# STM32L4P5AEI6 register map
File version: 1.0
Registers are 32-bit, access not given, reset 0x0 unless marked. A register's access mark holds for its fields unless they carry their own. Offsets are from the block's base; [hi:lo] are bit positions; {n}, {i} and the like mark numbered series.

## ADC1
Base 0x50040000
Same registers: ADC2 0x50040100
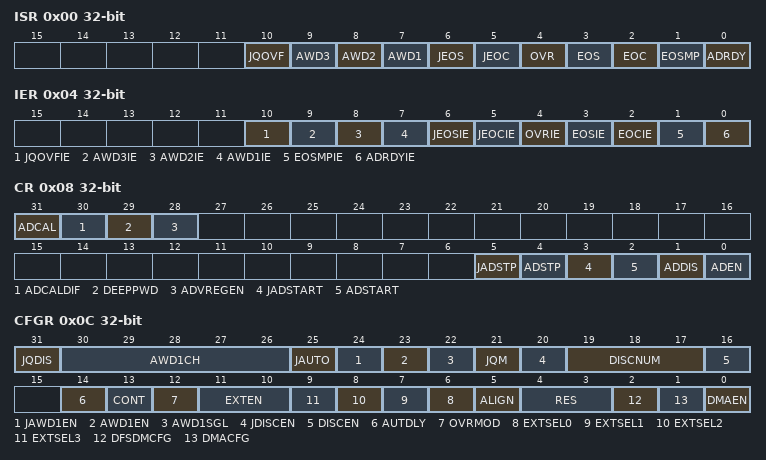
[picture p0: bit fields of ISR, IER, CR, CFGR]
0x00 ISR
  [10] JQOVF, [9] AWD3, [8] AWD2, [7] AWD1, [6] JEOS, [5] JEOC, [4] OVR, [3] EOS, [2] EOC, [1] EOSMP, [0] ADRDY
0x04 IER
  [10] JQOVFIE, [9] AWD3IE, [8] AWD2IE, [7] AWD1IE, [6] JEOSIE, [5] JEOCIE, [4] OVRIE, [3] EOSIE, [2] EOCIE, [1] EOSMPIE, [0] ADRDYIE
0x08 CR
  [31] ADCAL, [30] ADCALDIF, [29] DEEPPWD, [28] ADVREGEN, [5] JADSTP, [4] ADSTP, [3] JADSTART, [2] ADSTART, [1] ADDIS, [0] ADEN
0x0C CFGR
  [31] JQDIS, [30:26] AWD1CH, [25] JAUTO, [24] JAWD1EN, [23] AWD1EN, [22] AWD1SGL, [21] JQM, [20] JDISCEN, [19:17] DISCNUM, [16] DISCEN, [14] AUTDLY, [13] CONT, [12] OVRMOD, [11:10] EXTEN, [n+6] EXTSEL{n} (n=0..3), [5] ALIGN, [4:3] RES, [2] DFSDMCFG, [1] DMACFG, [0] DMAEN
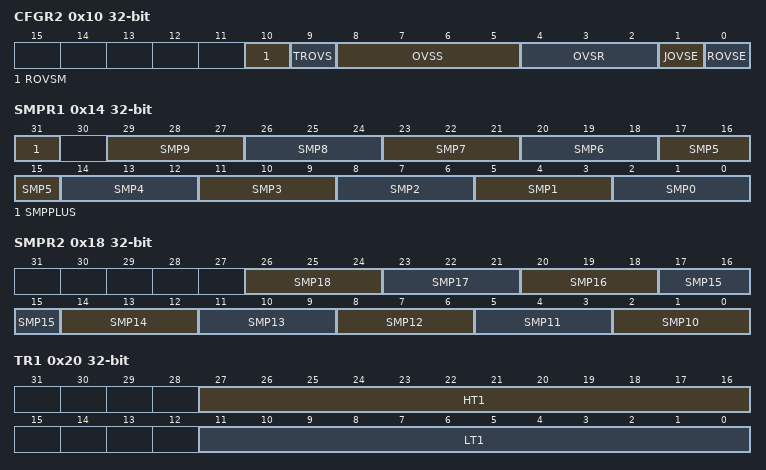
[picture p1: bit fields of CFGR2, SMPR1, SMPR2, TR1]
0x10 CFGR2
  [10] ROVSM, [9] TROVS, [8:5] OVSS, [4:2] OVSR, [1] JOVSE, [0] ROVSE
0x14 SMPR1
  [31] SMPPLUS, [3n+2:3n] SMP{n} (n=0..9)
0x18 SMPR2
  [3n-28:3n-30] SMP{n} (n=10..18)
0x20 TR1
  [27:16] HT1, [11:0] LT1
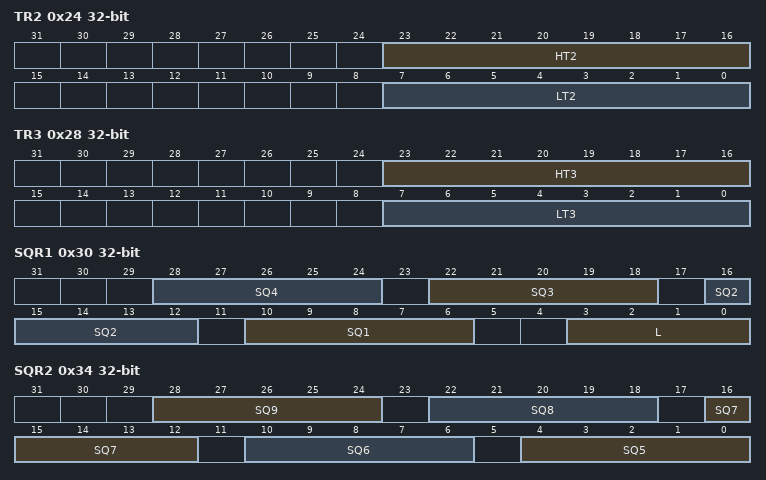
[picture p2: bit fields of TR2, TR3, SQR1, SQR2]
0x24 TR2
  [23:16] HT2, [7:0] LT2
0x28 TR3
  [23:16] HT3, [7:0] LT3
0x30 SQR1
  [6n+4:6n] SQ{n} (n=1..4), [3:0] L
0x34 SQR2
  [6n-26:6n-30] SQ{n} (n=5..9)
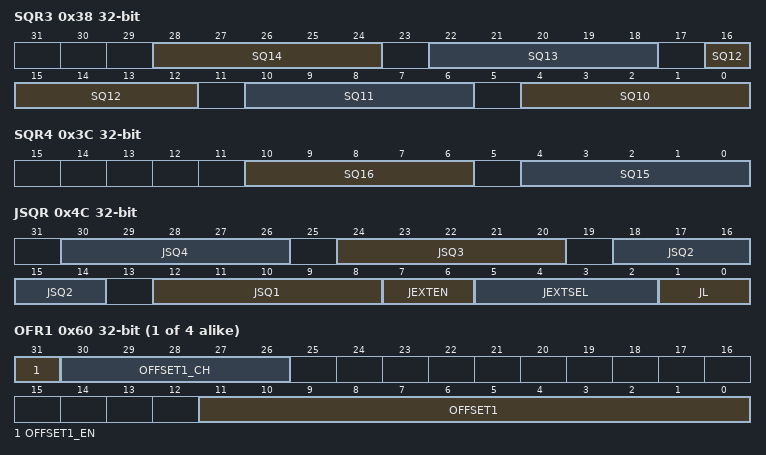
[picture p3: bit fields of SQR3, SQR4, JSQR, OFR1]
0x38 SQR3
  [6n-56:6n-60] SQ{n} (n=10..14)
0x3C SQR4
  [10:6] SQ16, [4:0] SQ15
0x40 DR
  [15:0] RDATA
0x4C JSQR
  [6n+6:6n+2] JSQ{n} (n=1..4), [7:6] JEXTEN, [5:2] JEXTSEL, [1:0] JL
{0x5C+4i} OFR{i} (i=1..4)
  [31] OFFSET{i}_EN, [30:26] OFFSET{i}_CH, [11:0] OFFSET{i}
{0x7C+4i} JDR{i} (i=1..4)
  [15:0] JDATA{i}
0xA0 AWD2CR
  [18:0] AWD2CH
0xA4 AWD3CR
  [18:0] AWD3CH
0xB0 DIFSEL
  [18:0] DIFSEL
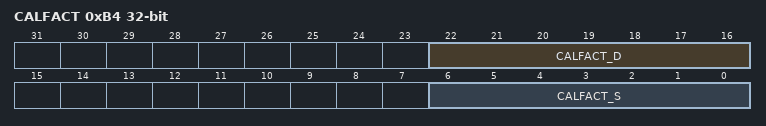
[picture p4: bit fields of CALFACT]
0xB4 CALFACT
  [22:16] CALFACT_D, [6:0] CALFACT_S

## DCMI
Base 0x50050000
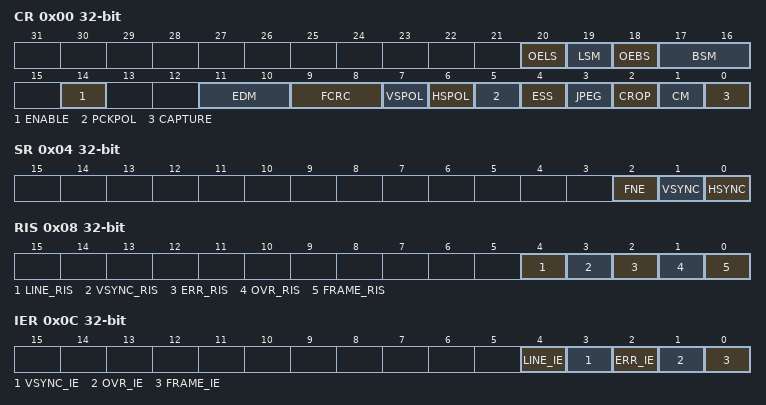
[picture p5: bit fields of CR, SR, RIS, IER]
0x00 CR
  [20] OELS, [19] LSM, [18] OEBS, [17:16] BSM, [14] ENABLE, [11:10] EDM, [9:8] FCRC, [7] VSPOL, [6] HSPOL, [5] PCKPOL, [4] ESS, [3] JPEG, [2] CROP, [1] CM, [0] CAPTURE
0x04 SR
  [2] FNE, [1] VSYNC, [0] HSYNC
0x08 RIS
  [4] LINE_RIS, [3] VSYNC_RIS, [2] ERR_RIS, [1] OVR_RIS, [0] FRAME_RIS
0x0C IER
  [4] LINE_IE, [3] VSYNC_IE, [2] ERR_IE, [1] OVR_IE, [0] FRAME_IE
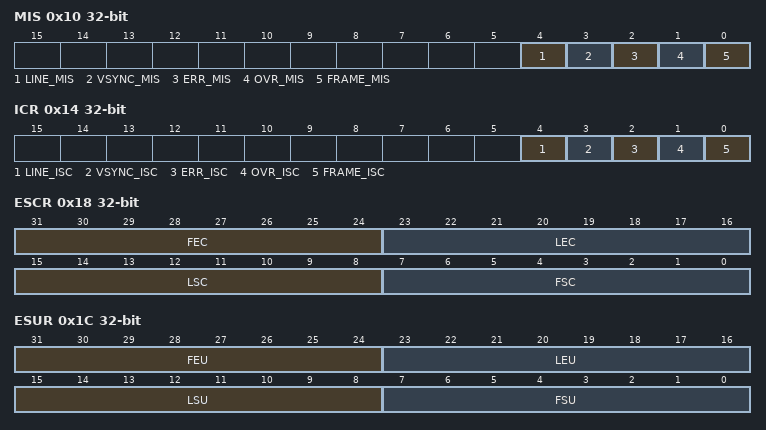
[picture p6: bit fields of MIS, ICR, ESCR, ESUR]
0x10 MIS
  [4] LINE_MIS, [3] VSYNC_MIS, [2] ERR_MIS, [1] OVR_MIS, [0] FRAME_MIS
0x14 ICR
  [4] LINE_ISC, [3] VSYNC_ISC, [2] ERR_ISC, [1] OVR_ISC, [0] FRAME_ISC
0x18 ESCR
  [31:24] FEC, [23:16] LEC, [15:8] LSC, [7:0] FSC
0x1C ESUR
  [31:24] FEU, [23:16] LEU, [15:8] LSU, [7:0] FSU
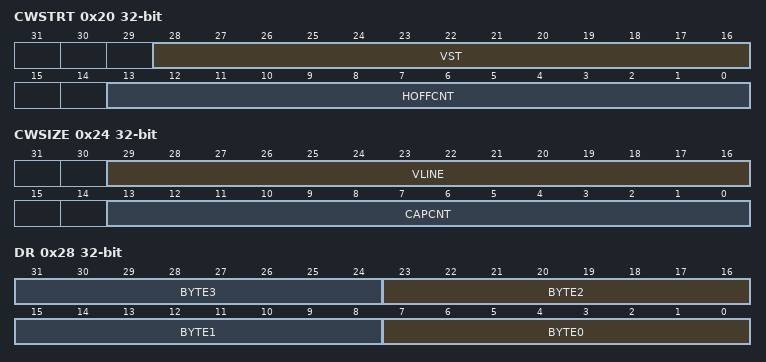
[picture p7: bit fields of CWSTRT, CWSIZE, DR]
0x20 CWSTRT
  [28:16] VST, [13:0] HOFFCNT
0x24 CWSIZE
  [29:16] VLINE, [13:0] CAPCNT
0x28 DR
  [8n+7:8n] BYTE{n} (n=0..3)

## PSSI
Base 0x50050400
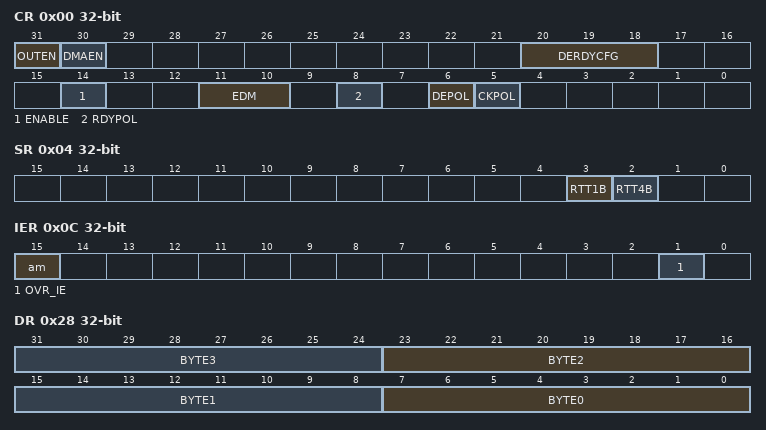
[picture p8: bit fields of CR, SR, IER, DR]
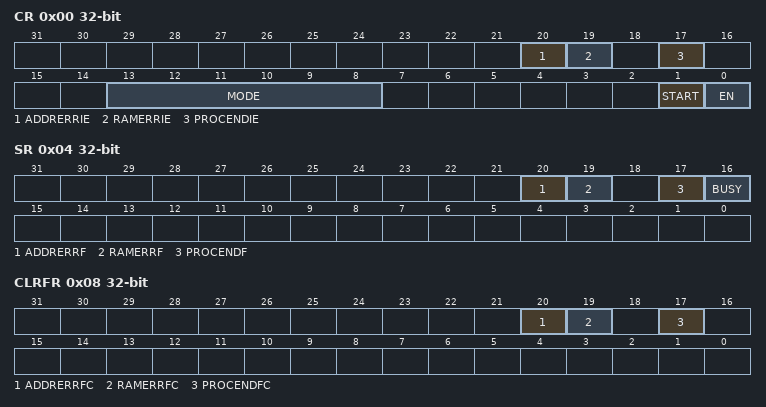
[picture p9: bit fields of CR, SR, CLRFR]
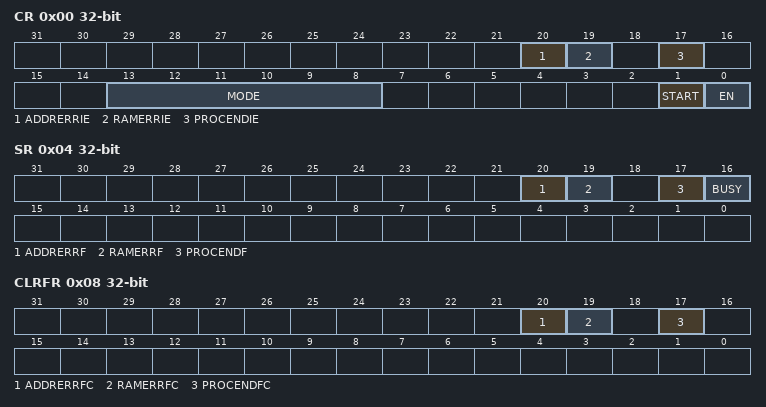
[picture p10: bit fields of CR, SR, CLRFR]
0x00 CR
  [31] OUTEN, [30] DMAEN, [20:18] DERDYCFG, [14] ENABLE, [11:10] EDM, [8] RDYPOL, [6] DEPOL, [5] CKPOL
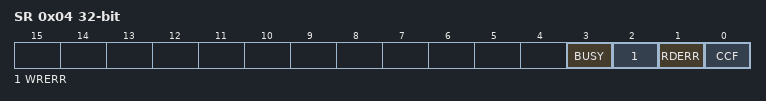
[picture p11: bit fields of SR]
0x04 SR
  [3] RTT1B, [2] RTT4B
0x08 RIS
  [1] OVR_RIS
0x0C IER
  [15] am, [1] OVR_IE
0x10 MIS
  [1] OVR_MIS
0x14 ICR
  [1] OVR_ISC
0x28 DR
  [8n+7:8n] BYTE{n} (n=0..3)

## RAM
Base 0x5005E000
0x00 CR
  [20] ADDRERRIE, [19] RAMERRIE, [17] PROCENDIE, [13:8] MODE, [1] START, [0] EN
0x04 SR
  [20] ADDRERRF, [19] RAMERRF, [17] PROCENDF, [16] BUSY
0x08 CLRFR
  [20] ADDRERRFC, [19] RAMERRFC, [17] PROCENDFC

## PKA
Base 0x5005E000
0x00 CR
  [20] ADDRERRIE, [19] RAMERRIE, [17] PROCENDIE, [13:8] MODE, [1] START, [0] EN
0x04 SR
  [20] ADDRERRF, [19] RAMERRF, [17] PROCENDF, [16] BUSY
0x08 CLRFR
  [20] ADDRERRFC, [19] RAMERRFC, [17] PROCENDFC

## AES
Base 0x50060000
0x00 CR
  [23:20] NPBLB, [18] KEYSIZE, [14:13] GCMPH, [12] DMAOUTEN, [11] DMAINEN, [10] ERRIE, [9] CCFIE, [8] ERRC, [7] CCFC, [16:5] CHMOD, [4:3] MODE, [2:1] DATATYPE, [0] EN
0x04 SR
  [3] BUSY, [2] WRERR, [1] RDERR, [0] CCF
0x08 DINR
  [31:0] DIN
0x0C DOUTR
  [31:0] DOUT
{0x10+4i} KEYR{i} (i=0..3)
  [31:0] KEY
{0x20+4i} IVR{i} (i=0..3)
  [31:0] IVI
{0x20+4i} KEYR{i} (i=4..7)
  [31:0] KEY
{0x40+4i} SUSP{i}R (i=0..7)
  [31:0] SUSP

## HASH
Base 0x50060400
0x00 CR
  [16] LKEY, [13] MDMAT, [12] DINNE, [11:8] NBW, [18:7] ALGO, [6] MODE, [5:4] DATATYPE, [3] DMAE, [2] INIT
0x04 DIN
  [31:0] DATAIN
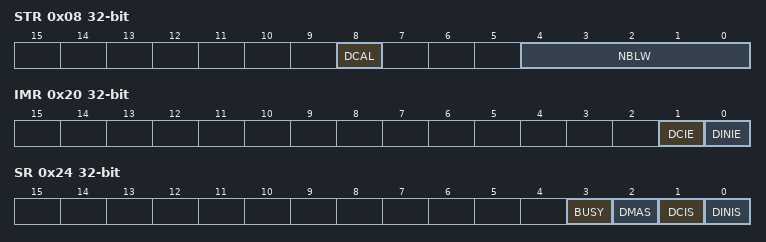
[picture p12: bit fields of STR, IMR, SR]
0x08 STR
  [8] DCAL, [4:0] NBLW
{0xC+4i} HRA{i} (i=0..4)
  [31:0] H{i}
0x20 IMR
  [1] DCIE, [0] DINIE
0x24 SR
  [3] BUSY, [2] DMAS, [1] DCIS, [0] DINIS
{0xF8+4i} CSR{i} (i=0..53)
  [31:0] CSx
{0x310+4i} HR{i} (i=0..7)
  [31:0] H{i}
